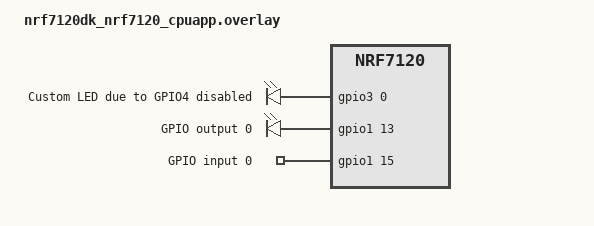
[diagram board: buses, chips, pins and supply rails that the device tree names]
/ {
	aliases {
		led = &led_custom0;
		out0 = &output0;
		in0 = &input0;
	};

	leds {
		led_custom0: led_custom0 {
			gpios = <&gpio3 0 GPIO_ACTIVE_HIGH>;
			label = "Custom LED due to GPIO4 disabled";
		};
	};

	outputs {
		compatible = "gpio-leds";

		output0: output_0 {
			gpios = <&gpio1 13 GPIO_ACTIVE_HIGH>;
			label = "GPIO output 0";
		};
	};

	inputs {
		compatible = "gpio-keys";

		input0: input_0 {
			gpios = <&gpio1 15 GPIO_ACTIVE_HIGH>;
			label = "GPIO input 0";
		};
	};
};

&gpio1 {
	status = "okay";
};

&gpio4 {
	status = "disabled";
};
